AUTOSAR XML (schema 00049)
package /ISOFT/PlatformComponents/nm/swc
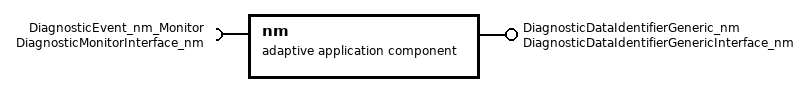
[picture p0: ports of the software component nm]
  adaptive application sw component type nm
    provide port DiagnosticDataIdentifierGeneric_nm: provided-interface=DiagnosticDataIdentifierGenericInterface_nm
    require port DiagnosticEvent_nm_Monitor: required-interface=DiagnosticMonitorInterface_nm
    adaptive swc internal behavior AdaptiveSwcInternalBehavior_nm
      swc service dependency DiagnosticDataIdentifierGeneric_nm: assigned-ports=role-based-port-assignment={port-prototype=DiagnosticDataIdentifierGeneric_nm, role=DiagnosticDataIdentifierGenericInterface}
        service-needs:
          diagnostic value needs DiagnosticValueNeeds: diagnostic-value-access=READ-ONLY
      swc service dependency DiagnosticEvent_nm_Monitor: assigned-ports=role-based-port-assignment={port-prototype=DiagnosticEvent_nm_Monitor, role=DiagnosticMonitorInterface}
        service-needs:
          diagnostic event needs DiagnosticEventNeeds
